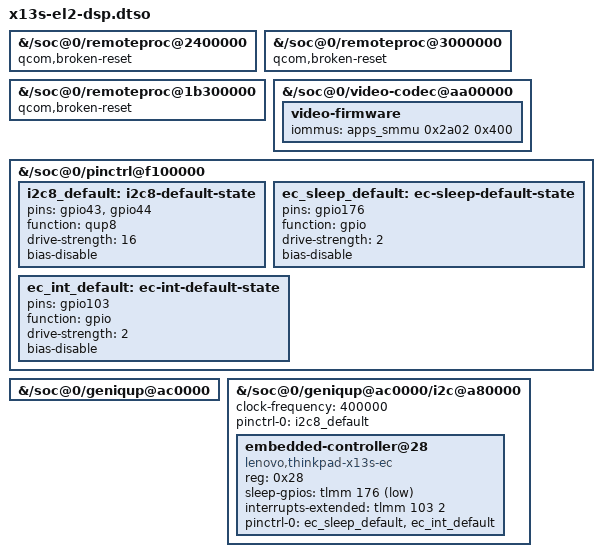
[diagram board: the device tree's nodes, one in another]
// SPDX-License-Identifier: BSD-3-Clause
/*
 * X13s at EL2 (slbounce): the DSPs are started from UEFI by qebspil and
 * Linux attaches to them. qcom,broken-reset makes qebspil start them and
 * makes the patched qcom_q6v5_pas take the attach-only path
 * (patches/linux/0007, 0008, 0010).
 */
/dts-v1/;
/plugin/;

&{/soc@0/remoteproc@2400000} {	/* slpi */
	qcom,broken-reset;
};

&{/soc@0/remoteproc@3000000} {	/* adsp */
	qcom,broken-reset;
};

&{/soc@0/remoteproc@1b300000} {	/* cdsp (nsp0) */
	qcom,broken-reset;
};

/*
 * Iris video codec (HW decode/encode). TZ can't PAS-boot it at EL2 (-22), so
 * patches/linux/0015 loads the firmware itself when this subnode exists: it
 * maps pil_video_mem at IOVA 0 for the firmware's own stream and releases the
 * XTSS reset. The firmware SID is not documented for sc8280xp; by analogy
 * with sc7180 (0x0c00/0x60 -> fw 0x0c42) it is 0x2a02, with mask 0x400 also
 * matching 0x2e02. Verified 2026-11-13: no SMMU faults, bit-exact decode.
 */
&{/soc@0/video-codec@aa00000} {
	video-firmware {
		iommus = <&apps_smmu 0x2a02 0x400>;
	};
};

/*
 * Embedded controller. The X13s DSDT puts the EC at 0x28 on \_SB.I2C9
 * (QUP1 SE0, 0xa80000 = i2c8), talking the same ECRD/ECWR protocol as the
 * ThinkPad T14s Gen6 EC. Driven by lenovo-thinkpad-x13s.c
 * (patches/linux/0013): Modern Standby notifications (power LED and lid dot
 * breathe in suspend), EC hotkeys and the mic-mute LED. GPIO 176 is the
 * SoC->EC sleep line the DSDT drives low on sleep entry (SGOV 0xB0); firmware
 * leaves it a high GPIO output. GPIO 103 is the EC event interrupt.
 * See notes/x13s-ec.md.
 */
&{/soc@0/pinctrl@f100000} {
	i2c8_default: i2c8-default-state {
		pins = "gpio43", "gpio44";
		function = "qup8";
		drive-strength = <16>;
		bias-disable;
	};

	ec_sleep_default: ec-sleep-default-state {
		pins = "gpio176";
		function = "gpio";
		drive-strength = <2>;
		bias-disable;
	};

	ec_int_default: ec-int-default-state {
		pins = "gpio103";
		function = "gpio";
		drive-strength = <2>;
		bias-disable;
	};
};

&{/soc@0/geniqup@ac0000} {
	status = "okay";
};

&{/soc@0/geniqup@ac0000/i2c@a80000} {
	clock-frequency = <400000>;
	pinctrl-names = "default";
	pinctrl-0 = <&i2c8_default>;
	status = "okay";
	#address-cells = <1>;
	#size-cells = <0>;

	embedded-controller@28 {
		compatible = "lenovo,thinkpad-x13s-ec";
		reg = <0x28>;
		/* <&tlmm 176 GPIO_ACTIVE_LOW>: asserted (low) = SoC asleep */
		sleep-gpios = <&tlmm 176 1>;
		/*
		 * <&tlmm 103 IRQ_TYPE_EDGE_FALLING>: EC event interrupt, pulsed
		 * low every ~100 ms while events are queued (ACPI GpioInt 0x300,
		 * located by watching edges while pressing F4).
		 */
		interrupts-extended = <&tlmm 103 2>;
		pinctrl-names = "default";
		pinctrl-0 = <&ec_sleep_default>, <&ec_int_default>;
	};
};
